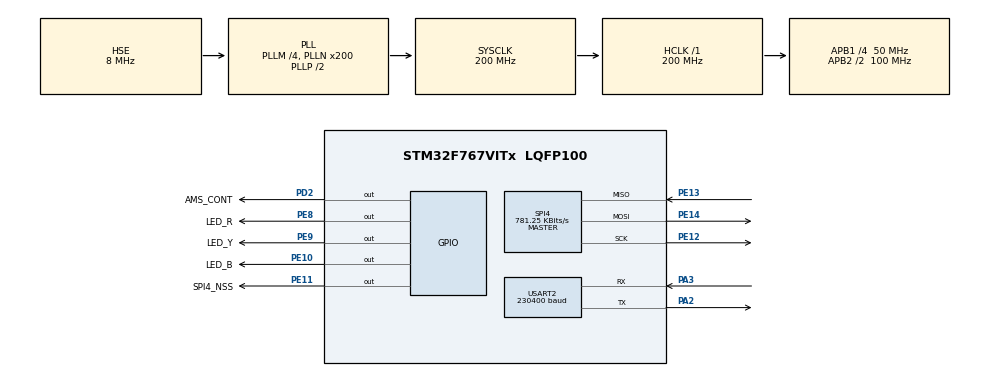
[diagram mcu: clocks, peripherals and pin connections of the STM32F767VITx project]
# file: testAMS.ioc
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CORTEX_M7.MPU_Control=__NULL
CORTEX_M7.default_mode_Activation=0
FREERTOS.Tasks01=mainTask,0,1000,mainTaskFunction,As weak,NULL,Dynamic,NULL,NULL;printTaskName,-2,1000,printTask,As external,NULL,Dynamic,NULL,NULL;AMS,3,1000,amsTask,As external,NULL,Dynamic,NULL,NULL
FREERTOS.configCHECK_FOR_STACK_OVERFLOW=2
FREERTOS.configGENERATE_RUN_TIME_STATS=1
FREERTOS.configTIMER_QUEUE_LENGTH=4
FREERTOS.configTIMER_TASK_PRIORITY=6
FREERTOS.configTIMER_TASK_STACK_DEPTH=1000
FREERTOS.configTOTAL_HEAP_SIZE=262144
FREERTOS.configUSE_COUNTING_SEMAPHORES=1
FREERTOS.configUSE_STATS_FORMATTING_FUNCTIONS=1
FREERTOS.configUSE_TIMERS=1
FREERTOS.configUSE_TRACE_FACILITY=1
Mcu.Family=STM32F7
Mcu.Name=STM32F767VITx
Mcu.Package=LQFP100
NVIC.PriorityGroup=NVIC_PRIORITYGROUP_4
NVIC.USART2_IRQn=true\:5\:0\:false\:false\:true\:true\:true\:true\:true
PA13.Mode=Serial_Wire
PA13.Signal=SYS_JTMS-SWDIO
PA14.Mode=Serial_Wire
PA14.Signal=SYS_JTCK-SWCLK
PA2.Mode=Asynchronous
PA2.Signal=USART2_TX
PA3.Mode=Asynchronous
PA3.Signal=USART2_RX
PD2.GPIO_Label=AMS_CONT
PD2.Signal=GPIO_Output
PE10.GPIO_Label=LED_B
PE10.Signal=GPIO_Output
PE11.GPIO_Label=SPI4_NSS
PE11.GPIO_PuPd=GPIO_PULLUP
PE11.GPIO_Speed=GPIO_SPEED_FREQ_VERY_HIGH
PE11.PinState=GPIO_PIN_SET
PE11.Signal=GPIO_Output
PE12.Mode=Full_Duplex_Master
PE12.Signal=SPI4_SCK
PE13.Mode=Full_Duplex_Master
PE13.Signal=SPI4_MISO
PE14.Mode=Full_Duplex_Master
PE14.Signal=SPI4_MOSI
PE8.GPIO_Label=LED_R
PE8.Signal=GPIO_Output
PE9.GPIO_Label=LED_Y
PE9.Signal=GPIO_Output
PH0/OSC_IN.Mode=HSE-External-Oscillator
PH0/OSC_IN.Signal=RCC_OSC_IN
PH1/OSC_OUT.Mode=HSE-External-Oscillator
PH1/OSC_OUT.Signal=RCC_OSC_OUT
ProjectManager.HeapSize=0x200
ProjectManager.StackSize=0x400
ProjectManager.TargetToolchain=Makefile
RCC.AHBFreq_Value=200000000
RCC.APB1CLKDivider=RCC_HCLK_DIV4
RCC.APB1Freq_Value=50000000
RCC.APB1TimFreq_Value=100000000
RCC.APB2CLKDivider=RCC_HCLK_DIV2
RCC.APB2Freq_Value=100000000
RCC.APB2TimFreq_Value=200000000
RCC.CortexFreq_Value=200000000
RCC.HCLKFreq_Value=200000000
RCC.HSE_VALUE=8000000
RCC.HSI_VALUE=16000000
RCC.LSE_VALUE=32768
RCC.PLLM=4
RCC.PLLN=200
RCC.PLLSourceVirtual=RCC_PLLSOURCE_HSE
RCC.SYSCLKFreq_VALUE=200000000
RCC.SYSCLKSource=RCC_SYSCLKSOURCE_PLLCLK
RCC.USBFreq_Value=200000000
RCC.VCOOutputFreq_Value=400000000
SPI4.BaudRatePrescaler=SPI_BAUDRATEPRESCALER_128
SPI4.CLKPhase=SPI_PHASE_2EDGE
SPI4.CLKPolarity=SPI_POLARITY_HIGH
SPI4.CalculateBaudRate=781.25 KBits/s
SPI4.DataSize=SPI_DATASIZE_8BIT
SPI4.Direction=SPI_DIRECTION_2LINES
SPI4.Mode=SPI_MODE_MASTER
SPI4.VirtualType=VM_MASTER
TIM9.Prescaler=200
USART2.BaudRate=230400
USART2.VirtualMode-Asynchronous=VM_ASYNC
VP_FREERTOS_VS_CMSIS_V1.Mode=CMSIS_V1
VP_TIM9_VS_ClockSourceINT.Mode=Internal
board=custom

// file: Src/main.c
/* USER CODE BEGIN Header */
/**
  ******************************************************************************
  * @file           : main.c
  * @brief          : Main program body
  ******************************************************************************
  * @attention
  *
  * Copyright (c) 2023 STMicroelectronics.
  * All rights reserved.
  *
  * This software is licensed under terms that can be found in the LICENSE file
  * in the root directory of this software component.
  * If no LICENSE file comes with this software, it is provided AS-IS.
  *
  ******************************************************************************
  */
/* USER CODE END Header */
#include "main.h"
#include "cmsis_os.h"
#include "spi.h"
#include "tim.h"
#include "usart.h"
#include "gpio.h"

/* USER CODE BEGIN Includes */
#include "debug.h"
#include "generalErrorHandler.h"
/* USER CODE END Includes */

void SystemClock_Config(void);
void MX_FREERTOS_Init(void);
/* USER CODE BEGIN PFP */
__weak void userInit() {}
/* USER CODE END PFP */

int main(void)
{

  /* MCU Configuration--------------------------------------------------------*/

  /* Reset of all peripherals, Initializes the Flash interface and the Systick. */
  HAL_Init();

  /* Configure the system clock */
  SystemClock_Config();

  /* Initialize all configured peripherals */
  MX_GPIO_Init();
  MX_SPI4_Init();
  MX_USART2_UART_Init();
  MX_TIM9_Init();
  /* USER CODE BEGIN 2 */
  userInit();
  /* USER CODE END 2 */

  /* Call init function for freertos objects (in freertos.c) */
  MX_FREERTOS_Init();

  /* Start scheduler */
  osKernelStart();

  /* We should never get here as control is now taken by the scheduler */
  /* Infinite loop */
  while (1)
  {

  }
}

void SystemClock_Config(void)
{
  RCC_OscInitTypeDef RCC_OscInitStruct = {0};
  RCC_ClkInitTypeDef RCC_ClkInitStruct = {0};

  /** Configure the main internal regulator output voltage
  */
  __HAL_RCC_PWR_CLK_ENABLE();
  __HAL_PWR_VOLTAGESCALING_CONFIG(PWR_REGULATOR_VOLTAGE_SCALE1);

  /** Initializes the RCC Oscillators according to the specified parameters
  * in the RCC_OscInitTypeDef structure.
  */
  RCC_OscInitStruct.OscillatorType = RCC_OSCILLATORTYPE_HSE;
  RCC_OscInitStruct.HSEState = RCC_HSE_ON;
  RCC_OscInitStruct.PLL.PLLState = RCC_PLL_ON;
  RCC_OscInitStruct.PLL.PLLSource = RCC_PLLSOURCE_HSE;
  RCC_OscInitStruct.PLL.PLLM = 4;
  RCC_OscInitStruct.PLL.PLLN = 200;
  RCC_OscInitStruct.PLL.PLLP = RCC_PLLP_DIV2;
  RCC_OscInitStruct.PLL.PLLQ = 2;
  RCC_OscInitStruct.PLL.PLLR = 2;
  if (HAL_RCC_OscConfig(&RCC_OscInitStruct) != HAL_OK)
  {
    Error_Handler();
  }

  /** Activate the Over-Drive mode
  */
  if (HAL_PWREx_EnableOverDrive() != HAL_OK)
  {
    Error_Handler();
  }

  /** Initializes the CPU, AHB and APB buses clocks
  */
  RCC_ClkInitStruct.ClockType = RCC_CLOCKTYPE_HCLK|RCC_CLOCKTYPE_SYSCLK
                              |RCC_CLOCKTYPE_PCLK1|RCC_CLOCKTYPE_PCLK2;
  RCC_ClkInitStruct.SYSCLKSource = RCC_SYSCLKSOURCE_PLLCLK;
  RCC_ClkInitStruct.AHBCLKDivider = RCC_SYSCLK_DIV1;
  RCC_ClkInitStruct.APB1CLKDivider = RCC_HCLK_DIV4;
  RCC_ClkInitStruct.APB2CLKDivider = RCC_HCLK_DIV2;

  if (HAL_RCC_ClockConfig(&RCC_ClkInitStruct, FLASH_LATENCY_6) != HAL_OK)
  {
    Error_Handler();
  }
}

void Error_Handler(void)
{
  /* USER CODE BEGIN Error_Handler_Debug */
  /* User can add his own implementation to report the HAL error return state */
  __disable_irq();
  while (1)
  {
    printf("ERROR OCCURRED. NOW IN ERROR HANDLER\n");
    HAL_Delay(3000);
  }
  /* USER CODE END Error_Handler_Debug */
}

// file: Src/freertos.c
/* USER CODE BEGIN Header */
/**
  ******************************************************************************
  * File Name          : freertos.c
  * Description        : Code for freertos applications
  ******************************************************************************
  * @attention
  *
  * Copyright (c) 2023 STMicroelectronics.
  * All rights reserved.
  *
  * This software is licensed under terms that can be found in the LICENSE file
  * in the root directory of this software component.
  * If no LICENSE file comes with this software, it is provided AS-IS.
  *
  ******************************************************************************
  */
/* USER CODE END Header */

#include "FreeRTOS.h"
#include "task.h"
#include "main.h"
#include "cmsis_os.h"

osThreadId mainTaskHandle;
osThreadId printTaskNameHandle;
osThreadId AMSHandle;

void mainTaskFunction(void const * argument);
extern void printTask(void const * argument);
extern void amsTask(void const * argument);

void MX_FREERTOS_Init(void); /* (MISRA C 2004 rule 8.1) */

/* GetIdleTaskMemory prototype (linked to static allocation support) */
void vApplicationGetIdleTaskMemory( StaticTask_t **ppxIdleTaskTCBBuffer, StackType_t **ppxIdleTaskStackBuffer, uint32_t *pulIdleTaskStackSize );

/* GetTimerTaskMemory prototype (linked to static allocation support) */
void vApplicationGetTimerTaskMemory( StaticTask_t **ppxTimerTaskTCBBuffer, StackType_t **ppxTimerTaskStackBuffer, uint32_t *pulTimerTaskStackSize );

/* Hook prototypes */
void configureTimerForRunTimeStats(void);
unsigned long getRunTimeCounterValue(void);
void vApplicationStackOverflowHook(xTaskHandle xTask, signed char *pcTaskName);

/* USER CODE BEGIN 1 */
/* Functions needed when configGENERATE_RUN_TIME_STATS is on */
__weak void configureTimerForRunTimeStats(void)
{

}

__weak unsigned long getRunTimeCounterValue(void)
{
return 0;
}
/* USER CODE END 1 */

/* USER CODE BEGIN 4 */
__weak void vApplicationStackOverflowHook(xTaskHandle xTask, signed char *pcTaskName)
{
   /* Run time stack overflow checking is performed if
   configCHECK_FOR_STACK_OVERFLOW is defined to 1 or 2. This hook function is
   called if a stack overflow is detected. */
}
/* USER CODE END 4 */

/* USER CODE BEGIN GET_IDLE_TASK_MEMORY */
static StaticTask_t xIdleTaskTCBBuffer;
static StackType_t xIdleStack[configMINIMAL_STACK_SIZE];

void vApplicationGetIdleTaskMemory( StaticTask_t **ppxIdleTaskTCBBuffer, StackType_t **ppxIdleTaskStackBuffer, uint32_t *pulIdleTaskStackSize )
{
  *ppxIdleTaskTCBBuffer = &xIdleTaskTCBBuffer;
  *ppxIdleTaskStackBuffer = &xIdleStack[0];
  *pulIdleTaskStackSize = configMINIMAL_STACK_SIZE;
  /* place for user code */
}
/* USER CODE END GET_IDLE_TASK_MEMORY */

/* USER CODE BEGIN GET_TIMER_TASK_MEMORY */
static StaticTask_t xTimerTaskTCBBuffer;
static StackType_t xTimerStack[configTIMER_TASK_STACK_DEPTH];

void vApplicationGetTimerTaskMemory( StaticTask_t **ppxTimerTaskTCBBuffer, StackType_t **ppxTimerTaskStackBuffer, uint32_t *pulTimerTaskStackSize )
{
  *ppxTimerTaskTCBBuffer = &xTimerTaskTCBBuffer;
  *ppxTimerTaskStackBuffer = &xTimerStack[0];
  *pulTimerTaskStackSize = configTIMER_TASK_STACK_DEPTH;
  /* place for user code */
}
/* USER CODE END GET_TIMER_TASK_MEMORY */

void MX_FREERTOS_Init(void) {

  /* Create the thread(s) */
  /* definition and creation of mainTask */
  osThreadDef(mainTask, mainTaskFunction, osPriorityNormal, 0, 1000);
  mainTaskHandle = osThreadCreate(osThread(mainTask), NULL);

  /* definition and creation of printTaskName */
  // osThreadDef(printTaskName, printTask, osPriorityLow, 0, 1000);
  // printTaskNameHandle = osThreadCreate(osThread(printTaskName), NULL);

  /* definition and creation of AMS */
  osThreadDef(AMS, amsTask, osPriorityRealtime, 0, 1000);
  AMSHandle = osThreadCreate(osThread(AMS), NULL);

}

__weak void mainTaskFunction(void const * argument)
{
  for(;;)
  {
    osDelay(1);
  }
}
